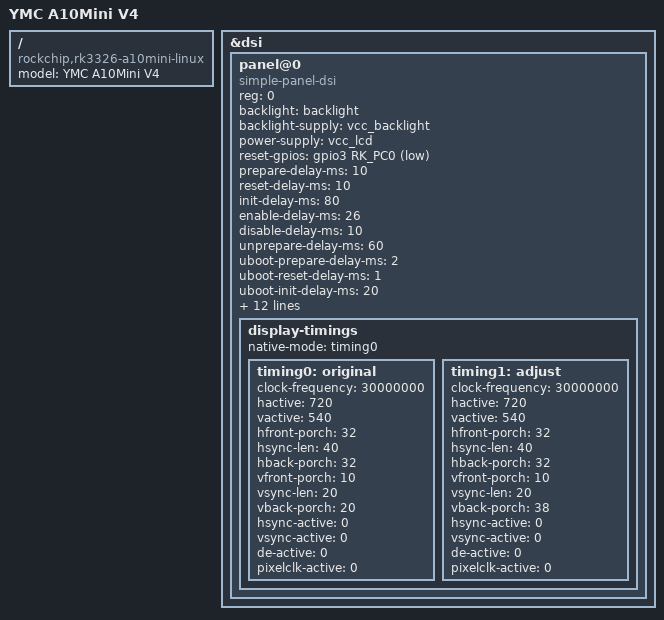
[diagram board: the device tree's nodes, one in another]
// SPDX-License-Identifier: (GPL-2.0+ OR MIT)
/*
* Copyright (c) 2026 kk&lcdyk
*
* YMC A10MINI V4
*
*/

/dts-v1/;
#include "rk3326-a10mini-linux.dts"

/ {
	model = "YMC A10Mini V4";
	compatible = "rockchip,rk3326-a10mini-linux", "rockchip,rk3326";
};

&dsi {
	status = "okay";
	
	panel@0 {
		compatible = "simple-panel-dsi";
		reg = <0>;
		/* pwm1 backlight */
		backlight = <&backlight>;
		/* RK817 LDO7 */
		backlight-supply = <&vcc_backlight>;
		/* RK817 LDO8 */
		power-supply = <&vcc_lcd>;
		/* Rev 0.2 LCD reset gpio GPIO3.C0 */
		reset-gpios = <&gpio3 RK_PC0 GPIO_ACTIVE_LOW>;
		prepare-delay-ms = <10>;
		reset-delay-ms = <10>;
		init-delay-ms = <80>;
		enable-delay-ms = <26>;
		disable-delay-ms = <10>;
		unprepare-delay-ms = <60>;
		uboot-prepare-delay-ms = <2>;
		uboot-reset-delay-ms = <1>;
		uboot-init-delay-ms = <20>;
		uboot-enable-delay-ms = <120>;
		uboot-disable-delay-ms = <50>;
		uboot-unprepare-delay-ms = <20>;
		width-mm = <43>;
		height-mm = <57>;
		dsi,flags  = <(MIPI_DSI_MODE_VIDEO |
		MIPI_DSI_MODE_VIDEO_BURST |
		MIPI_DSI_MODE_LPM |
		MIPI_DSI_MODE_EOT_PACKET)>;
		dsi,format = <MIPI_DSI_FMT_RGB888>;
		dsi,lanes = <2>;
		panel-init-sequence = [39 00 05 ff aa 55 a5 80 39 00 06 f0 55 aa 52 08 00 15 00 02 36 00 39 00 03 b1 68 27 15 00 02 b5 0f 15 00 02 b6 0c 39 00 05 b8 01 02 08 02 15 00 02 ba 02 39 00 03 bb 24 24 39 00 03 bc 00 00 39 00 06 bd 02 68 20 20 00 39 00 06 be 02 68 20 20 00 39 00 07 cc 41 36 87 00 00 00 39 00 07 ce 10 10 10 10 10 10 39 00 06 f0 55 aa 52 08 06 39 00 03 b0 2e 2e 39 00 03 c2 17 11 05 78 01 11 05 78 01 29];
		panel-exit-sequence = <0x5140128 0x50a0110>;
		
		display-timings {
			native-mode = <&timing0>;
			
			// 30.00MHz / (720+32+40+32)×(540+10+20+20) = 30,000,000 / 824×590 = 61.71 Hz
			timing0: original {
				clock-frequency = <30000000>;
				hactive = <720>;
				vactive = <540>;
				hfront-porch = <32>;
				hsync-len = <40>;
				hback-porch = <32>;
				vfront-porch = <10>;
				vsync-len = <20>;
				vback-porch = <20>;
				hsync-active = <0>;
				vsync-active = <0>;
				de-active = <0>;
				pixelclk-active = <0>;
			};
			
			// 30.00MHz / (720+32+40+32)×(540+10+20+38) = 30,000,000 / 824×608 = 59.88 Hz
			timing1: adjust {
				clock-frequency = <30000000>;
				hactive = <720>;
				vactive = <540>;
				hfront-porch = <32>;
				hsync-len = <40>;
				hback-porch = <32>;
				vfront-porch = <10>;
				vsync-len = <20>;
				vback-porch = <38>;
				hsync-active = <0>;
				vsync-active = <0>;
				de-active = <0>;
				pixelclk-active = <0>;
			};
		};
	};
};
